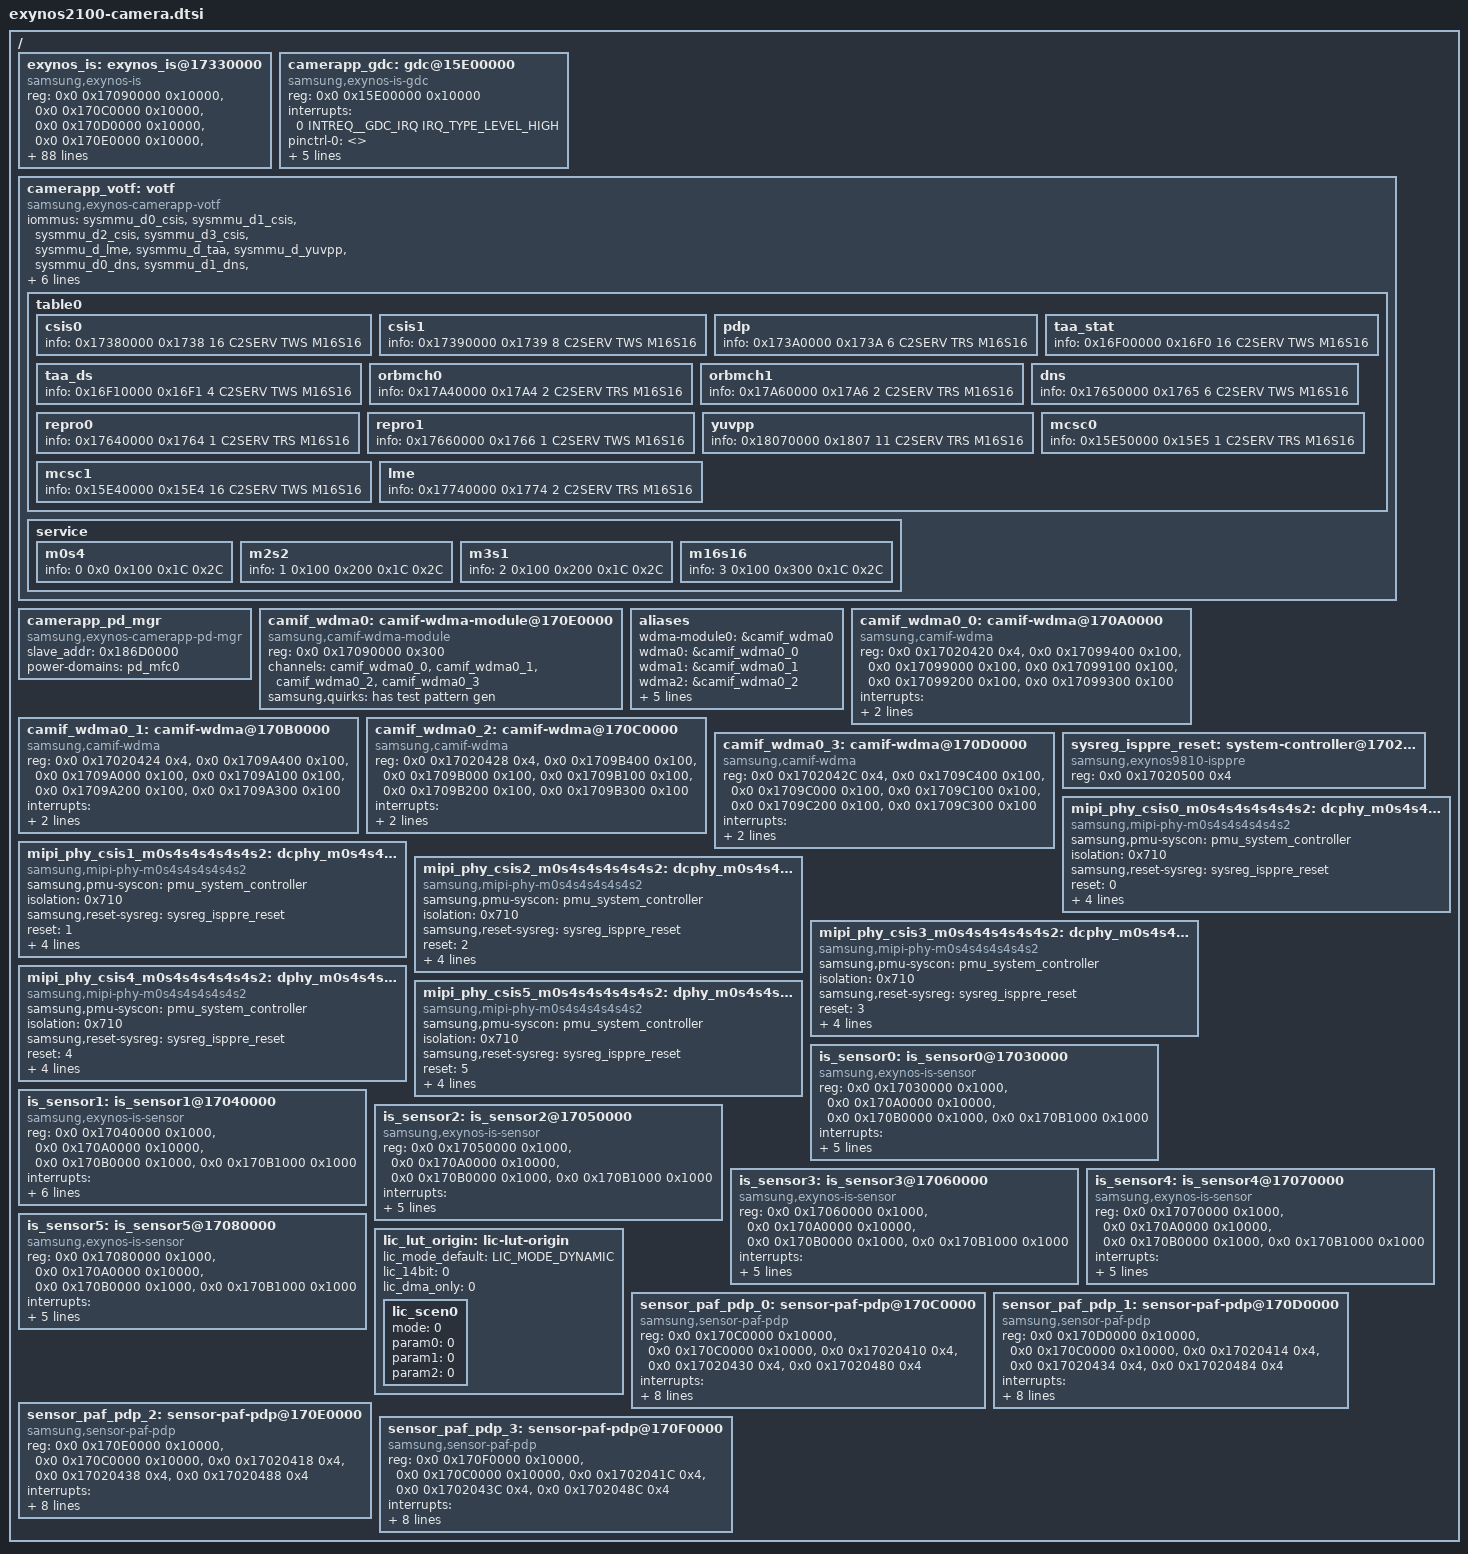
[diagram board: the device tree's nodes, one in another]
/*
 * SAMSUNG EXYNOS2100 SoC camera device tree source
 *
 * Copyright (c) 2020 Samsung Electronics Co., Ltd.
 *		http://www.samsung.com
 *
 * SAMSUNG EXYNOS2100 SoC camera device nodes are listed in this file.
 * EXYNOS2100 based board files can include this file and provide
 * values for board specfic bindings.
 *
 * This program is free software; you can redistribute it and/or modify
 * it under the terms of the GNU General Public License version 2 as
 * published by the Free Software Foundation.
 */

#include <dt-bindings/clock/exynos2100.h>
#include <dt-bindings/interrupt-controller/arm-gic.h>
#include <dt-bindings/interrupt-controller/exynos2100.h>
#include <dt-bindings/camera/exynos_is_dt.h>
#include <dt-bindings/camera/votf.h>
#include "exynos2100-pinctrl.dtsi"

/ {
	exynos_is: exynos_is@17330000 {
		compatible = "samsung,exynos-is";
		reg = <0x0 0x17090000 0x10000>, /* CSIS DMA  */
			<0x0 0x170C0000 0x10000>, /* PDP CORE0 */
			<0x0 0x170D0000 0x10000>, /* PDP CORE1 */
			<0x0 0x170E0000 0x10000>, /* PDP CORE2 */
			<0x0 0x170F0000 0x10000>, /* PDP CORE3 */
			<0x0 0x16E80000 0x40000>, /* TAA0 */
			<0x0 0x16E80000 0x40000>, /* TAA1 */
			<0x0 0x16E80000 0x40000>, /* TAA2 */
			<0x0 0x16E80000 0x40000>, /* TAA3 */
			<0x0 0x17090000 0x10000>, /* ZSL/STRIP DMA  */
			<0x0 0x17A30000 0x10000>, /* ORBMCH0 */
			<0x0 0x17A50000 0x10000>, /* ORBMCH1 */
			<0x0 0x17730000 0x10000>, /* LME */
			<0x0 0x17430000 0x40000>, /* ITP */
			<0x0 0x179A0000 0x40000>, /* MCFP0 */
			<0x0 0x17B40000 0x40000>, /* MCFP1 */
			<0x0 0x17600000 0x40000>, /* DNS */
			<0x0 0x18030000 0x40000>, /* YUVPP */
			<0x0 0x15C50000 0x10000>; /* MCSC */
		interrupts = <0 INTREQ__TAA_CH0_0 IRQ_TYPE_LEVEL_HIGH>, /*TAA0_0 */
			   <0 INTREQ__TAA_CH0_1 IRQ_TYPE_LEVEL_HIGH>,   /* TAA0_1 */
			   <0 INTREQ__ZSL_DMA0 IRQ_TYPE_LEVEL_HIGH>,    /* ZSL_DMA_0 */
			   <0 INTREQ__STRP_DMA0 IRQ_TYPE_LEVEL_HIGH>,    /* STRP_DMA_0 */

			   <0 INTREQ__TAA_CH1_0 IRQ_TYPE_LEVEL_HIGH>, /*TAA1_0 */
			   <0 INTREQ__TAA_CH1_1 IRQ_TYPE_LEVEL_HIGH>,   /* TAA1_1 */
			   <0 INTREQ__ZSL_DMA1 IRQ_TYPE_LEVEL_HIGH>,    /* ZSL_DMA_1 */
			   <0 INTREQ__STRP_DMA1 IRQ_TYPE_LEVEL_HIGH>,    /* STRP_DMA_1 */

			   <0 INTREQ__TAA_CH2_0 IRQ_TYPE_LEVEL_HIGH>, /*TAA2_0 */
			   <0 INTREQ__TAA_CH2_1 IRQ_TYPE_LEVEL_HIGH>,   /* TAA2_1 */
			   <0 INTREQ__ZSL_DMA2 IRQ_TYPE_LEVEL_HIGH>,    /* ZSL_DMA_2 */
			   <0 INTREQ__STRP_DMA2 IRQ_TYPE_LEVEL_HIGH>,    /* STRP_DMA_2 */

			   <0 INTREQ__TAA_CH3_0 IRQ_TYPE_LEVEL_HIGH>, /*TAA3_0 */
			   <0 INTREQ__TAA_CH3_1 IRQ_TYPE_LEVEL_HIGH>,   /* TAA3_1 */
			   <0 INTREQ__ZSL_DMA3 IRQ_TYPE_LEVEL_HIGH>,    /* ZSL_DMA_3 */
			   <0 INTREQ__STRP_DMA3 IRQ_TYPE_LEVEL_HIGH>,    /* STRP_DMA_3 */

			   <0 INTREQ__LME_O_INT0 IRQ_TYPE_LEVEL_HIGH>,   /* LME_0 */
			   <0 INTREQ__LME_O_INT1 IRQ_TYPE_LEVEL_HIGH>,   /* LME_0 */
			   <0 INTREQ__ORBMCH0_O_INT IRQ_TYPE_LEVEL_HIGH>, /* ORBMCH_0 */
			   <0 INTREQ__ORBMCH1_O_INT IRQ_TYPE_LEVEL_HIGH>, /* ORBMCH_1 */

			   <0 INTREQ__DNS0_0 IRQ_TYPE_LEVEL_HIGH>,    /* ITP_0 */
			   <0 INTREQ__DNS0_1 IRQ_TYPE_LEVEL_HIGH>,    /* ITP_1 */
			   <0 INTREQ__MCFP0_0 IRQ_TYPE_LEVEL_HIGH>,     /* MCFP0_0 */
			   <0 INTREQ__MCFP0_1 IRQ_TYPE_LEVEL_HIGH>,     /* MCFP0_1 */
			   <0 INTREQ__YUVPP IRQ_TYPE_LEVEL_HIGH>,     /* YUVPP */
			   <0 INTREQ__MCSC_OTF0 IRQ_TYPE_LEVEL_HIGH>;   /* MCSC_0 */
		pinctrl-names = "default","release";
		pinctrl-0 = <>;
		pinctrl-1 = <>;
		clocks = <&clock GATE_DFTMUX_CMU_QCH_CIS_CLK0>,
		      <&clock GATE_DFTMUX_CMU_QCH_CIS_CLK1>,
		      <&clock GATE_DFTMUX_CMU_QCH_CIS_CLK2>,
		      <&clock GATE_DFTMUX_CMU_QCH_CIS_CLK3>,
		      <&clock GATE_DFTMUX_CMU_QCH_CIS_CLK4>,
		      <&clock GATE_DFTMUX_CMU_QCH_CIS_CLK5>,

		      <&clock CIS_CLK0>,
		      <&clock CIS_CLK1>,
		      <&clock CIS_CLK2>,
		      <&clock CIS_CLK3>,
		      <&clock CIS_CLK4>,
		      <&clock CIS_CLK5>,

		      <&clock GATE_CSISX6_QCH_DMA>,

		      <&clock GATE_MIPI_PHY_LINK_WRAP_QCH_CSIS0>,
		      <&clock GATE_MIPI_PHY_LINK_WRAP_QCH_CSIS1>,
		      <&clock GATE_MIPI_PHY_LINK_WRAP_QCH_CSIS2>,
		      <&clock GATE_MIPI_PHY_LINK_WRAP_QCH_CSIS3>,
		      <&clock GATE_MIPI_PHY_LINK_WRAP_QCH_CSIS4>,
		      <&clock GATE_MIPI_PHY_LINK_WRAP_QCH_CSIS5>,

		      <&clock GATE_PDP_TOP_QCH_PDP_TOP>,
		      <&clock GATE_ADD_TAA_QCH>,
		      <&clock GATE_ORBMCH0_QCH>,
		      <&clock GATE_ORBMCH1_QCH>,
		      <&clock GATE_LME_QCH>,
		      <&clock GATE_MCFP0_QCH>,
		      <&clock GATE_MCFP1_QCH>,
		      <&clock GATE_DNS_QCH>,
		      <&clock GATE_ITP_QCH>,
		      <&clock GATE_YUVPP_TOP_QCH>,
		      <&clock GATE_MCSC_QCH>,
		      <&clock GATE_GDC_QCH>;
		clock-names = "GATE_DFTMUX_CMU_QCH_CIS_CLK0",
			"GATE_DFTMUX_CMU_QCH_CIS_CLK1",
			"GATE_DFTMUX_CMU_QCH_CIS_CLK2",
			"GATE_DFTMUX_CMU_QCH_CIS_CLK3",
			"GATE_DFTMUX_CMU_QCH_CIS_CLK4",
			"GATE_DFTMUX_CMU_QCH_CIS_CLK5",

			"CIS_CLK0",
			"CIS_CLK1",
			"CIS_CLK2",
			"CIS_CLK3",
			"CIS_CLK4",
			"CIS_CLK5",

			"GATE_CSISX6_QCH_DMA",

			"GATE_MIPI_PHY_LINK_WRAP_QCH_CSIS0",
			"GATE_MIPI_PHY_LINK_WRAP_QCH_CSIS1",
			"GATE_MIPI_PHY_LINK_WRAP_QCH_CSIS2",
			"GATE_MIPI_PHY_LINK_WRAP_QCH_CSIS3",
			"GATE_MIPI_PHY_LINK_WRAP_QCH_CSIS4",
			"GATE_MIPI_PHY_LINK_WRAP_QCH_CSIS5",

			"GATE_PDP_TOP_QCH_PDP_TOP",
			"GATE_ADD_TAA_QCH",
			"GATE_ORBMCH0_QCH",
			"GATE_ORBMCH1_QCH",
			"GATE_LME_QCH",
			"GATE_MCFP0_QCH",
			"GATE_MCFP1_QCH",
			"GATE_DNS_QCH",
			"GATE_ITP_QCH",
			"GATE_YUVPP_TOP_QCH",
			"GATE_MCSC_QCH",
			"GATE_GDC_QCH";
		status = "ok";
		iommus = <&sysmmu_d0_csis>,
		       <&sysmmu_d1_csis>,
		       <&sysmmu_d2_csis>,
		       <&sysmmu_d3_csis>,
		       <&sysmmu_d_lme>,
		       <&sysmmu_d_taa>,
		       <&sysmmu_d_yuvpp>,
		       <&sysmmu_d0_dns>,
		       <&sysmmu_d1_dns>,
		       <&sysmmu_d1_mcsc>,
		       <&sysmmu_d2_mcsc>,
		       <&sysmmu_d0_mcfp0>,
		       <&sysmmu_d1_mcfp0>,
		       <&sysmmu_d2_mcfp0>,
		       <&sysmmu_d3_mcfp0>,
		       <&sysmmu_d0_mcfp1>;
		samsung,iommu-group = <&iommu_group_is>;
		#cooling-cells = <2>; /* min followed by max */
		ewf-index = <EWF_GRP_CAM>;
		list-scen-bts = "camera_default", "camera_heavy";
		num_of_3aa = <4>;
		num_of_lme = <1>;
		num_of_isp = <1>;
		num_of_mcsc = <1>;
		num_of_vra = <0>;
		num_of_clh = <0>;
		num_of_ypp = <1>;

		memory-region = <&camera_rmem>;
		samsung,tzmp;
	};

	camerapp_gdc: gdc@15E00000 {
		compatible = "samsung,exynos-is-gdc";
		reg = <0x0 0x15E00000 0x10000>; /* GDC */
		interrupts = <0 INTREQ__GDC_IRQ IRQ_TYPE_LEVEL_HIGH>; /* GDC */
		pinctrl-names = "default","release";
		pinctrl-0 = <>;
		pinctrl-1 = <>;
		clocks = <&clock GATE_GDC_QCH>;
		clock-names = "gate";
		status = "okay";
		iommus = <&sysmmu_d0_mcsc>;
		samsung,iommu-group = <&iommu_group_camerapp_gdc>;
		#cooling-cells = <2>; /* min followed by max */
		dma-coherent;
	};

	camerapp_votf: votf {
		compatible = "samsung,exynos-camerapp-votf";
		iommus = <&sysmmu_d0_csis>,
			<&sysmmu_d1_csis>,
			<&sysmmu_d2_csis>,
			<&sysmmu_d3_csis>,
			<&sysmmu_d_lme>,
			<&sysmmu_d_taa>,
			<&sysmmu_d_yuvpp>,
			<&sysmmu_d0_dns>,
			<&sysmmu_d1_dns>,
			<&sysmmu_d1_mcsc>,
			<&sysmmu_d2_mcsc>,
			<&sysmmu_d0_mcfp0>,
			<&sysmmu_d1_mcfp0>,
			<&sysmmu_d2_mcfp0>,
			<&sysmmu_d3_mcfp0>,
			<&sysmmu_d0_mcfp1>;
		samsung,iommu-group = <&iommu_group_is>;
		status = "okay";
		use_axi;

		table0{
			/* base address, ip num, id cnt, C2SERV/C2AGENT, TWS/TRS, module type */
			csis0    { info = <0x17380000 0x1738 16 C2SERV TWS M16S16>; };
			csis1    { info = <0x17390000 0x1739 8  C2SERV TWS M16S16>; };
			pdp      { info = <0x173A0000 0x173A 6  C2SERV TRS M16S16>; };
			taa_stat { info = <0x16F00000 0x16F0 16 C2SERV TWS M16S16>; }; /* 3AA_STAT */
			taa_ds   { info = <0x16F10000 0x16F1 4  C2SERV TWS M16S16>; }; /* 3AA_DS */
			orbmch0  { info = <0x17A40000 0x17A4 2  C2SERV TRS M16S16>; }; /* ORBMCH0 */
			orbmch1  { info = <0x17A60000 0x17A6 2  C2SERV TRS M16S16>; }; /* ORBMCH1 */
			dns      { info = <0x17650000 0x1765 6  C2SERV TWS M16S16>; }; /* DNS_VOTF1 */
			repro0   { info = <0x17640000 0x1764 1  C2SERV TRS M16S16>; }; /* DNS_VOTF0 */
			repro1   { info = <0x17660000 0x1766 1  C2SERV TWS M16S16>; }; /* DNS_VOTF2 */
			yuvpp    { info = <0x18070000 0x1807 11 C2SERV TRS M16S16>; }; /* VOTF_YUVPP */
			mcsc0    { info = <0x15E50000 0x15E5 1  C2SERV TRS M16S16>; }; /* MCSC_R_VOTF */
			mcsc1    { info = <0x15E40000 0x15E4 16 C2SERV TWS M16S16>; }; /* MCSC_W_VOTF */
			/* gdc0     { info = <0x15E20000 0x15E2 2  C2SERV TRS M16S16>; }; */ /* GDC_VOTF1(R) */
			/* gdc1     { info = <0x15E10000 0x15E1 2  C2SERV TWS M16S16>; }; */ /* GDC_VOTF0(W) */
			lme      { info = <0x17740000 0x1774 2  C2SERV TRS M16S16>; }; /* LME */
		};

		service {
			/* num, tws addr, trs addr, tws gap, trs gap */
			m0s4 { info = <0 0x0 0x100 0x1C 0x2C>; };
			m2s2 { info = <1 0x100 0x200 0x1C 0x2C>; };
			m3s1 { info = <2 0x100 0x200 0x1C 0x2C>; };
			m16s16 { info = <3 0x100 0x300 0x1C 0x2C>; };
		};
	};

	camerapp_pd_mgr: camerapp_pd_mgr {
		compatible = "samsung,exynos-camerapp-pd-mgr";
		slave_addr = <0x186D0000>; /* MFC0 */
		power-domains = <&pd_mfc0>;
		status = "okay";
	};

	camif_wdma0: camif-wdma-module@170E0000 {
		compatible = "samsung,camif-wdma-module";
		reg = <0x0 0x17090000 0x300>;
		reg-names = "ctl";
		channels = <&camif_wdma0_0>,
			<&camif_wdma0_1>,
			<&camif_wdma0_2>,
			<&camif_wdma0_3>;
		samsung,quirks = "has test pattern gen";
	};

	aliases {
		wdma-module0 = &camif_wdma0;
	};

	camif_wdma0_0: camif-wdma@170A0000 {
		compatible = "samsung,camif-wdma";
		reg = <0x0 0x17020420 0x4>,	/* input MUX */
			<0x0 0x17099400 0x100>,	/* CTL */
			<0x0 0x17099000 0x100>,	/* VC0 */
			<0x0 0x17099100 0x100>,	/* VC1 */
			<0x0 0x17099200 0x100>,	/* VC2 */
			<0x0 0x17099300 0x100>;	/* VC3 */
		reg-names = "mux", "ctl", "vc0", "vc1", "vc2", "vc3";
		interrupts = <GIC_SPI INTREQ__CSIS_DMA0 IRQ_TYPE_LEVEL_HIGH>;
		interrupt-names = "dma";
		module = <&camif_wdma0>;
	};

	camif_wdma0_1: camif-wdma@170B0000 {
		compatible = "samsung,camif-wdma";
		reg = <0x0 0x17020424 0x4>,	/* input MUX */
			<0x0 0x1709A400 0x100>,	/* CTL */
			<0x0 0x1709A000 0x100>,	/* VC0 */
			<0x0 0x1709A100 0x100>,	/* VC1 */
			<0x0 0x1709A200 0x100>,	/* VC2 */
			<0x0 0x1709A300 0x100>;	/* VC3 */
		reg-names = "mux", "ctl", "vc0", "vc1", "vc2", "vc3";
		interrupts = <GIC_SPI INTREQ__CSIS_DMA1 IRQ_TYPE_LEVEL_HIGH>;
		interrupt-names = "dma";
		module = <&camif_wdma0>;
	};

	camif_wdma0_2: camif-wdma@170C0000 {
		compatible = "samsung,camif-wdma";
		reg = <0x0 0x17020428 0x4>,	/* input MUX */
			<0x0 0x1709B400 0x100>,	/* CTL */
			<0x0 0x1709B000 0x100>,	/* VC0 */
			<0x0 0x1709B100 0x100>,	/* VC1 */
			<0x0 0x1709B200 0x100>,	/* VC2 */
			<0x0 0x1709B300 0x100>;	/* VC3 */
		reg-names = "mux", "ctl", "vc0", "vc1", "vc2", "vc3";
		interrupts = <GIC_SPI INTREQ__CSIS_DMA2 IRQ_TYPE_LEVEL_HIGH>;
		interrupt-names = "dma";
		module = <&camif_wdma0>;
	};

	camif_wdma0_3: camif-wdma@170D0000 {
		compatible = "samsung,camif-wdma";
		reg = <0x0 0x1702042C 0x4>,	/* input MUX */
			<0x0 0x1709C400 0x100>,	/* CTL */
			<0x0 0x1709C000 0x100>,	/* VC0 */
			<0x0 0x1709C100 0x100>,	/* VC1 */
			<0x0 0x1709C200 0x100>,	/* VC2 */
			<0x0 0x1709C300 0x100>;	/* VC3 */
		reg-names = "mux", "ctl", "vc0", "vc1", "vc2", "vc3";
		interrupts = <GIC_SPI INTREQ__CSIS_DMA3 IRQ_TYPE_LEVEL_HIGH>;
		interrupt-names = "dma";
		module = <&camif_wdma0>;
	};

	aliases {
		wdma0 = &camif_wdma0_0;
		wdma1 = &camif_wdma0_1;
		wdma2 = &camif_wdma0_2;
		wdma3 = &camif_wdma0_3;
	};

	sysreg_isppre_reset: system-controller@17020500 {
		compatible = "samsung,exynos9810-isppre", "syscon";
		reg = <0x0 0x17020500 0x4>;
	};

	mipi_phy_csis0_m0s4s4s4s4s4s2: dcphy_m0s4s4s4s4s4s2_csi0@17020500 {
		/* DPHY 6.5 Gbps 4lane */
		/* CPHY 4.5 Gbps 3lane */
		compatible = "samsung,mipi-phy-m0s4s4s4s4s4s2";
		samsung,pmu-syscon = <&pmu_system_controller>;
		isolation = <0x710>; /* PMU address offset */
		samsung,reset-sysreg = <&sysreg_isppre_reset>;
		reset = <0>; /* reset bit */
		reg = <0x0 0x170A1300 0x500>;
		owner = <1>; /* 0: DSI,  1: CSI */
		#phy-cells = <1>;
		ldo0 = "vdd_0p85";
		ldo1 = "vdd_1p8";
	};

	mipi_phy_csis1_m0s4s4s4s4s4s2: dcphy_m0s4s4s4s4s4s2_csi1@17020500 {
		/* DPHY 6.5 Gbps 4lane */
		/* CPHY 4.5 Gbps 3lane */
		compatible = "samsung,mipi-phy-m0s4s4s4s4s4s2";
		samsung,pmu-syscon = <&pmu_system_controller>;
		isolation = <0x710>; /* PMU address offset */
		samsung,reset-sysreg = <&sysreg_isppre_reset>;
		reset = <1>; /* reset bit */
		reg = <0x0 0x170A1B00 0x500>;
		owner = <1>; /* 0: DSI,  1: CSI */
		#phy-cells = <1>;
		ldo0 = "vdd_0p85";
		ldo1 = "vdd_1p8";
	};

	mipi_phy_csis2_m0s4s4s4s4s4s2: dcphy_m0s4s4s4s4s4s2_csi2@17020500 {
		/* DPHY 6.5 Gbps 4lane */
		/* CPHY 4.5 Gbps 3lane */
		compatible = "samsung,mipi-phy-m0s4s4s4s4s4s2";
		samsung,pmu-syscon = <&pmu_system_controller>;
		isolation = <0x710>; /* PMU address offset */
		samsung,reset-sysreg = <&sysreg_isppre_reset>;
		reset = <2>; /* reset bit */
		reg = <0x0 0x170A2300 0x500>;
		owner = <1>; /* 0: DSI,  1: CSI */
		#phy-cells = <1>;
		ldo0 = "vdd_0p85";
		ldo1 = "vdd_1p8";
	};

	mipi_phy_csis3_m0s4s4s4s4s4s2: dcphy_m0s4s4s4s4s4s2_csi3@17020500 {
		/* DPHY 6.5 Gbps 4lane */
		/* CPHY 4.5 Gbps 3lane */
		compatible = "samsung,mipi-phy-m0s4s4s4s4s4s2";
		samsung,pmu-syscon = <&pmu_system_controller>;
		isolation = <0x710>; /* PMU address offset */
		samsung,reset-sysreg = <&sysreg_isppre_reset>;
		reset = <3>; /* reset bit */
		reg = <0x0 0x170A2B00 0x500>;
		owner = <1>; /* 0: DSI,  1: CSI */
		#phy-cells = <1>;
		ldo0 = "vdd_0p85";
		ldo1 = "vdd_1p8";
	};

	mipi_phy_csis4_m0s4s4s4s4s4s2: dphy_m0s4s4s4s4s4s2_csi4@17020500 {
		/* DPHY 6.5 Gbps 4lane */
		compatible = "samsung,mipi-phy-m0s4s4s4s4s4s2";
		samsung,pmu-syscon = <&pmu_system_controller>;
		isolation = <0x710>; /* PMU address offset */
		samsung,reset-sysreg = <&sysreg_isppre_reset>;
		reset = <4>; /* reset bit */
		reg = <0x0 0x170A3300 0x500>;
		owner = <1>; /* 0: DSI,  1: CSI */
		#phy-cells = <1>;
		ldo0 = "vdd_0p85";
		ldo1 = "vdd_1p8";
	};

	mipi_phy_csis5_m0s4s4s4s4s4s2: dphy_m0s4s4s4s4s4s2_csi5@17020500 {
		/* DPHY 6.5 Gbps 2lane */
		compatible = "samsung,mipi-phy-m0s4s4s4s4s4s2";
		samsung,pmu-syscon = <&pmu_system_controller>;
		isolation = <0x710>; /* PMU address offset */
		samsung,reset-sysreg = <&sysreg_isppre_reset>;
		reset = <5>; /* reset bit */
		reg = <0x0 0x170A3B00 0x300>;
		owner = <1>; /* 0: DSI,  1: CSI */
		#phy-cells = <1>;
		ldo0 = "vdd_0p85";
		ldo1 = "vdd_1p8";
	};

	is_sensor0: is_sensor0@17030000 {
		/* CSIS0 */
		compatible = "samsung,exynos-is-sensor";
		#address-cells = <1>;
		#size-cells = <1>;
		reg = <0x0 0x17030000 0x1000>, /* MIPI-CSI0 */
			<0x0 0x170A0000 0x10000>, /* PHY: M0S4S4S4S4S4S2 */
			<0x0 0x170B0000 0x1000>, /* MCB */
			<0x0 0x170B1000 0x1000>; /* EBUF */
		reg-names = "csi", "phy", "mcb", "ebuf";
		interrupts = <0 INTREQ__CSIS0 IRQ_TYPE_LEVEL_HIGH>, /*MIPI-CSI0 */
			<0 INTREQ__STRP_DMA0 IRQ_TYPE_LEVEL_HIGH>;
		interrupt-names = "csi", "ebuf";
		phys = <&mipi_phy_csis0_m0s4s4s4s4s4s2 0>;
		phy-names = "csis_dphy";
		iommus = <&sysmmu_d0_csis>, <&sysmmu_d1_csis>;
		samsung,iommu-group = <&iommu_group_is>;
	};

	is_sensor1: is_sensor1@17040000 {
		/* CSIS1 */
		compatible = "samsung,exynos-is-sensor";
		#address-cells = <1>;
		#size-cells = <1>;
		reg = <0x0 0x17040000 0x1000>, /* MIPI-CSI1 */
			<0x0 0x170A0000 0x10000>, /* PHY: M0S4S4S4S4S4S2 */
			<0x0 0x170B0000 0x1000>, /* MCB */
			<0x0 0x170B1000 0x1000>; /* EBUF */
		reg-names = "csi", "phy", "mcb", "ebuf";
		interrupts = <0 INTREQ__CSIS1 IRQ_TYPE_LEVEL_HIGH>, /* MIPI-CSI1 */
			<0 INTREQ__STRP_DMA0 IRQ_TYPE_LEVEL_HIGH>;
		interrupt-names = "csi", "ebuf";
		phys = <&mipi_phy_csis1_m0s4s4s4s4s4s2 0>;
		phy-names = "csis_dphy";
		iommus = <&sysmmu_d0_csis>, <&sysmmu_d1_csis>;
		samsung,iommu-group = <&iommu_group_is>;
		samsung,tzmp;
	};

	is_sensor2: is_sensor2@17050000 {
		/* CSIS2 */
		compatible = "samsung,exynos-is-sensor";
		#address-cells = <1>;
		#size-cells = <1>;
		reg = <0x0 0x17050000 0x1000>, /* MIPI-CSI2 */
			<0x0 0x170A0000 0x10000>, /* PHY: M0S4S4S4S4S4S2 */
			<0x0 0x170B0000 0x1000>, /* MCB */
			<0x0 0x170B1000 0x1000>; /* EBUF */
		reg-names = "csi", "phy", "mcb", "ebuf";
		interrupts = <0 INTREQ__CSIS2 IRQ_TYPE_LEVEL_HIGH>, /* MIPI-CSI2 */
			<0 INTREQ__STRP_DMA0 IRQ_TYPE_LEVEL_HIGH>;
		interrupt-names = "csi", "ebuf";
		phys = <&mipi_phy_csis2_m0s4s4s4s4s4s2 0>;
		phy-names = "csis_dphy";
		iommus = <&sysmmu_d0_csis>, <&sysmmu_d1_csis>;
		samsung,iommu-group = <&iommu_group_is>;
	};

	is_sensor3: is_sensor3@17060000 {
		/* CSIS3 */
		compatible = "samsung,exynos-is-sensor";
		#address-cells = <1>;
		#size-cells = <1>;
		reg = <0x0 0x17060000 0x1000>, /* MIPI-CSI3 */
			<0x0 0x170A0000 0x10000>, /* PHY: M0S4S4S4S4S4S2 */
			<0x0 0x170B0000 0x1000>, /* MCB */
			<0x0 0x170B1000 0x1000>; /* EBUF */
		reg-names = "csi", "phy", "mcb", "ebuf";
		interrupts = <0 INTREQ__CSIS3 IRQ_TYPE_LEVEL_HIGH>, /* MIPI-CSI3 */
			<0 INTREQ__STRP_DMA0 IRQ_TYPE_LEVEL_HIGH>;
		interrupt-names = "csi", "ebuf";
		phys = <&mipi_phy_csis3_m0s4s4s4s4s4s2 0>;
		phy-names = "csis_dphy";
		iommus = <&sysmmu_d0_csis>, <&sysmmu_d1_csis>;
		samsung,iommu-group = <&iommu_group_is>;
	};

	is_sensor4: is_sensor4@17070000 {
		/* CSIS4 */
		compatible = "samsung,exynos-is-sensor";
		#address-cells = <1>;
		#size-cells = <1>;
		reg = <0x0 0x17070000 0x1000>, /* MIPI-CSI4 */
			<0x0 0x170A0000 0x10000>, /* PHY: M0S4S4S4S4S4S2 */
			<0x0 0x170B0000 0x1000>, /* MCB */
			<0x0 0x170B1000 0x1000>; /* EBUF */
		reg-names = "csi", "phy", "mcb", "ebuf";
		interrupts = <0 INTREQ__CSIS4 IRQ_TYPE_LEVEL_HIGH>, /* MIPI-CSI4 */
			<0 INTREQ__STRP_DMA0 IRQ_TYPE_LEVEL_HIGH>;
		interrupt-names = "csi", "ebuf";
		phys = <&mipi_phy_csis4_m0s4s4s4s4s4s2 0>;
		phy-names = "csis_dphy";
		iommus = <&sysmmu_d0_csis>, <&sysmmu_d1_csis>;
		samsung,iommu-group = <&iommu_group_is>;
	};

	is_sensor5: is_sensor5@17080000 {
		/* CSIS5 */
		compatible = "samsung,exynos-is-sensor";
		#address-cells = <1>;
		#size-cells = <1>;
		reg = <0x0 0x17080000 0x1000>, /* MIPI-CSI5 */
			<0x0 0x170A0000 0x10000>, /* PHY: M0S4S4S4S4S4S2 */
			<0x0 0x170B0000 0x1000>, /* MCB */
			<0x0 0x170B1000 0x1000>; /* EBUF */
		reg-names = "csi", "phy", "mcb", "ebuf";
		interrupts = <0 INTREQ__CSIS5 IRQ_TYPE_LEVEL_HIGH>, /* MIPI-CSI5 */
			<0 INTREQ__STRP_DMA0 IRQ_TYPE_LEVEL_HIGH>;
		interrupt-names = "csi", "ebuf";
		phys = <&mipi_phy_csis5_m0s4s4s4s4s4s2 0>;
		phy-names = "csis_dphy";
		iommus = <&sysmmu_d0_csis>, <&sysmmu_d1_csis>;
		samsung,iommu-group = <&iommu_group_is>;
	};

	lic_lut_origin: lic-lut-origin {
		#define LIC_MODE_DYNAMIC	(0)
		#define LIC_MODE_STATIC		(1)
		#define LIC_PATH_OTF		(0)
		#define LIC_PATH_DMA		(1)

		lic_mode_default = <LIC_MODE_DYNAMIC>;
		lic_14bit = <0>;
		lic_dma_only = <0>; /* Use this when NOT using OTF input at all. */

		/*
		 * When DYNAMIC mode is selected, param means enable limitation for DMA path.
		 * Example:
		 * @ mode = <LIC_MODE_DYNAMIC>;
		 * @ param0 = <LIC_PATH_OTF>;
		 * @ param1 = <LIC_PATH_DMA>;
		 * @ param2 = <LIC_PATH_OTF>;
		 *
		 * When STATIC mode is selected, param means buffer size for each context.
		 * Example:
		 * @ mode = <LIC_MODE_STAIC>;
		 * @ param0 = <3584>;
		 * @ param1 = <3583>;
		 * @ param2 = <1>;
		 *
		 * The lic_scen0 is not abailable. If the index of LUT is "0", the selection is skipped.
		 */
		lic_scen0 { /* Reserved */
			mode = <0>;
			param0 = <0>;
			param1 = <0>;
			param2 = <0>;
		};
	};

	sensor_paf_pdp_0: sensor-paf-pdp@170C0000 {
		/* PDP CORE0 */
		compatible = "samsung,sensor-paf-pdp";
		reg = <0x0 0x170C0000 0x10000>, /* PDP CORE0 */
			<0x0 0x170C0000 0x10000>, /* PDP CORE0: For common regiser */
			<0x0 0x17020410 0x4>, /* PDP input mux(CSIS_PDP_SC_CON0) in SYSREG */
			<0x0 0x17020430 0x4>, /* PDP input vc mux(CSIS_PDP_VC_CON0) in SYSREG */
			<0x0 0x17020480 0x4>; /* CSIS_PDP_SC_PDP_IN_EN in SYSREG */
		reg-names = "core", "common", "mux", "vc_mux", "en";
		interrupts = <0 INTREQ__PDP0 IRQ_TYPE_LEVEL_HIGH>,
			<0 INTREQ__PDP1 IRQ_TYPE_LEVEL_HIGH>;
		mux =  <0 1 2 3 4 5>; /* <csi0 csi1 csi2 csi3 csi4 csi5> */
		vc_mux = <0x1 0x1 0x1 0x1 0x1 0x1>; /* <csi0 csi1 csi2 csi3 csi4 csi5> */
		en =  <0 1 2 3 4 5>; /* bit postion: <csi0 csi1 csi2 csi3 csi4 csi5> */
		leader; /* have RDMA & create video node */
		lic_lut = <&lic_lut_origin>;
		clocks = <&clock GATE_PDP_TOP_QCH_PDP_TOP>;
		clock-names = "GATE_PDP_TOP_QCH_PDP_TOP";
	};

	sensor_paf_pdp_1: sensor-paf-pdp@170D0000 {
		/* PDP CORE0 */
		compatible = "samsung,sensor-paf-pdp";
		reg = <0x0 0x170D0000 0x10000>, /* PDP CORE0 */
			<0x0 0x170C0000 0x10000>, /* PDP CORE0: For common regiser */
			<0x0 0x17020414 0x4>, /* PDP input mux(CSIS_PDP_SC_CON0) in SYSREG */
			<0x0 0x17020434 0x4>, /* PDP input vc mux(CSIS_PDP_VC_CON0) in SYSREG */
			<0x0 0x17020484 0x4>; /* CSIS_PDP_SC_PDP_IN_EN in SYSREG */
		reg-names = "core", "common", "mux", "vc_mux", "en";
		interrupts = <0 INTREQ__PDP2 IRQ_TYPE_LEVEL_HIGH>,
			<0 INTREQ__PDP3 IRQ_TYPE_LEVEL_HIGH>;
		mux =  <0 1 2 3 4 5>; /* <csi0 csi1 csi2 csi3 csi4 csi5> */
		vc_mux = <0x1 0x1 0x1 0x1 0x1 0x1>; /* <csi0 csi1 csi2 csi3 csi4 csi5> */
		en =  <0 1 2 3 4 5>; /* bit postion: <csi0 csi1 csi2 csi3 csi4 csi5> */
		leader; /* have RDMA & create video node */
		lic_lut = <&lic_lut_origin>;
		clocks = <&clock GATE_PDP_TOP_QCH_PDP_TOP>;
		clock-names = "GATE_PDP_TOP_QCH_PDP_TOP";
	};

	sensor_paf_pdp_2: sensor-paf-pdp@170E0000 {
		/* PDP CORE0 */
		compatible = "samsung,sensor-paf-pdp";
		reg = <0x0 0x170E0000 0x10000>, /* PDP CORE0 */
			<0x0 0x170C0000 0x10000>, /* PDP CORE0: For common regiser */
			<0x0 0x17020418 0x4>, /* PDP input mux(CSIS_PDP_SC_CON0) in SYSREG */
			<0x0 0x17020438 0x4>, /* PDP input vc mux(CSIS_PDP_VC_CON0) in SYSREG */
			<0x0 0x17020488 0x4>; /* CSIS_PDP_SC_PDP_IN_EN in SYSREG */
		reg-names = "core", "common", "mux", "vc_mux", "en";
		interrupts = <0 INTREQ__PDP4 IRQ_TYPE_LEVEL_HIGH>,
			<0 INTREQ__PDP5 IRQ_TYPE_LEVEL_HIGH>;
		mux =  <0 1 2 3 4 5>; /* <csi0 csi1 csi2 csi3 csi4 csi5> */
		vc_mux = <0x1 0x1 0x1 0x1 0x1 0x1>; /* <csi0 csi1 csi2 csi3 csi4 csi5> */
		en =  <0 1 2 3 4 5>; /* bit postion: <csi0 csi1 csi2 csi3 csi4 csi5> */
		leader; /* have RDMA & create video node */
		lic_lut = <&lic_lut_origin>;
		clocks = <&clock GATE_PDP_TOP_QCH_PDP_TOP>;
		clock-names = "GATE_PDP_TOP_QCH_PDP_TOP";
	};

	sensor_paf_pdp_3: sensor-paf-pdp@170F0000 {
		/* PDP CORE0 */
		compatible = "samsung,sensor-paf-pdp";
		reg = <0x0 0x170F0000 0x10000>, /* PDP CORE0 */
			<0x0 0x170C0000 0x10000>, /* PDP CORE0: For common regiser */
			<0x0 0x1702041C 0x4>, /* PDP input mux(CSIS_PDP_SC_CON0) in SYSREG */
			<0x0 0x1702043C 0x4>, /* PDP input vc mux(CSIS_PDP_VC_CON0) in SYSREG */
			<0x0 0x1702048C 0x4>; /* CSIS_PDP_SC_PDP_IN_EN in SYSREG */
		reg-names = "core", "common", "mux", "vc_mux", "en";
		interrupts = <0 INTREQ__PDP6 IRQ_TYPE_LEVEL_HIGH>,
			<0 INTREQ__PDP7 IRQ_TYPE_LEVEL_HIGH>;
		mux =  <0 1 2 3 4 5>; /* <csi0 csi1 csi2 csi3 csi4 csi5> */
		vc_mux = <0x1 0x1 0x1 0x1 0x1 0x1>; /* <csi0 csi1 csi2 csi3 csi4 csi5> */
		en =  <0 1 2 3 4 5>; /* bit postion: <csi0 csi1 csi2 csi3 csi4 csi5> */
		leader; /* have RDMA & create video node */
		lic_lut = <&lic_lut_origin>;
		clocks = <&clock GATE_PDP_TOP_QCH_PDP_TOP>;
		clock-names = "GATE_PDP_TOP_QCH_PDP_TOP";
	};

	aliases {
		pdp0 = &sensor_paf_pdp_0;
		pdp1 = &sensor_paf_pdp_1;
		pdp2 = &sensor_paf_pdp_2;
		pdp3 = &sensor_paf_pdp_3;
	};

	/* TODO: enable OIS MCU */
#if 0
	ois_mcu: ois_mcu@173F0000 {
		/* OIS_MCU */
		compatible = "samsung,sensor-ois-mcu";
		reg = <0x0 0x173F0000 0x10000>,	/* OIS MCU (SRAM 56KB) */
			<0x0 0x109A0000 0x10000>,	/* I2C: USI17_I2C */
			<0x0 0x109E0000 0x10000>;	/* SPI: USI18_USI */
		reg-names = "core", "i2c", "spi";
		interrupts = <0 INTREQ__OIS_MCU_CSIS IRQ_TYPE_LEVEL_HIGH>;
		id = <0 2>;
		ois_gyro_list = <0x01 0x01 0x10 0x00 0x00>;

		power-domains = <&pd_csis>;
		clocks = <&clock UMUX_CLKCMU_CSIS_OIS_MCU>;
		clock-names = "user_mux";
	};
#endif
};
